VERSION ""

NS_ :

BS_:

BU_: VCU BMS ECUMASTER_GPS_IMU AMK_RL

BO_ 256 VCU_STATUS: 4 Vector__XXX
 SG_ VEHICLE_STATE : 0|2@1+ (1,0) [0|3] "Enum" Vector__XXX
 SG_ TORQUE_PLAUSIBLE : 2|1@1+ (1,0) [0|1] "Bool" Vector__XXX
 SG_ PEDALS_PLAUSIBLE : 3|1@1+ (1,0) [0|1] "Bool" Vector__XXX
 SG_ TORQUE_DERATING : 4|1@1+ (1,0) [0|0] "Bool" Vector__XXX
 SG_ VCU_EEPROM_STATE : 5|2@1+ (1,0) [0|0] "Enum" Vector__XXX
 SG_ CAN_PLAUSIBLE : 7|1@1+ (1,0) [0|1] "Bool" Vector__XXX
 SG_ APPS_1_PLAUSIBLE : 8|1@1+ (1,0) [0|1] "Bool" Vector__XXX
 SG_ APPS_1_CONFIG_PLAUSIBLE : 9|1@1+ (1,0) [0|1] "Bool" Vector__XXX
 SG_ APPS_2_PLAUSIBLE : 10|1@1+ (1,0) [0|1] "Bool" Vector__XXX
 SG_ APPS_2_CONFIG_PLAUSIBLE : 11|1@1+ (1,0) [0|1] "Bool" Vector__XXX
 SG_ BSE_F_PLAUSIBLE : 12|1@1+ (1,0) [0|1] "Bool" Vector__XXX
 SG_ BSE_F_CONFIG_PLAUSIBLE : 13|1@1+ (1,0) [0|1] "Bool" Vector__XXX
 SG_ BSE_R_PLAUSIBLE : 14|1@1+ (1,0) [0|1] "Bool" Vector__XXX
 SG_ BSE_R_CONFIG_PLAUSIBLE : 15|1@1+ (1,0) [0|1] "Bool" Vector__XXX
 SG_ AMK_RL_VALID : 16|1@1+ (1,0) [0|0] "Bool" Vector__XXX
 SG_ AMK_RR_VALID : 17|1@1+ (1,0) [0|0] "Bool" Vector__XXX
 SG_ AMK_FL_VALID : 18|1@1+ (1,0) [0|0] "Bool" Vector__XXX
 SG_ AMK_FR_VALID : 19|1@1+ (1,0) [0|0] "Bool" Vector__XXX
 SG_ GPS_VALID : 20|1@1+ (1,0) [0|0] "Bool" Vector__XXX
 SG_ GLV_BATTERY_VOLTAGE : 24|8@1+ (0.070588235294,0) [0|18] "V" Vector__XXX

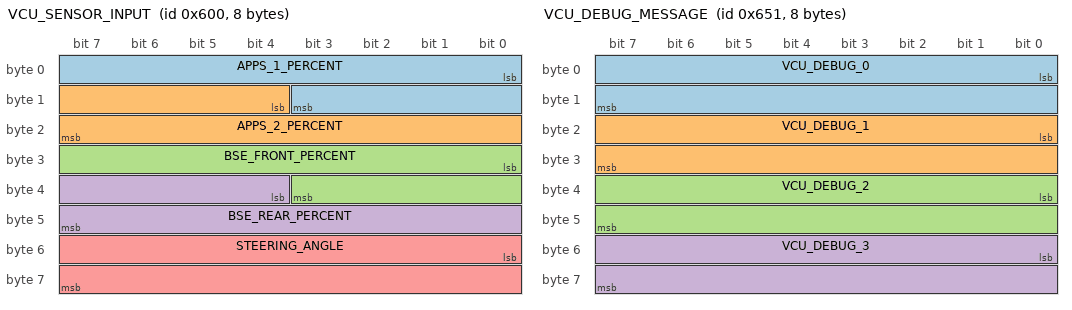
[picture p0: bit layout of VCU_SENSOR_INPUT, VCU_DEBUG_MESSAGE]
BO_ 1536 VCU_SENSOR_INPUT: 8 VCU
 SG_ APPS_1_PERCENT : 0|12@1+ (0.02442002442002442,0) [0|100] "%" Vector__XXX
 SG_ APPS_2_PERCENT : 12|12@1+ (0.02442002442002442,0) [0|100] "%" Vector__XXX
 SG_ BSE_FRONT_PERCENT : 24|12@1+ (0.02442002442002442,0) [0|100] "%" Vector__XXX
 SG_ BSE_REAR_PERCENT : 36|12@1+ (0.02442002442002442,0) [0|100] "%" Vector__XXX
 SG_ STEERING_ANGLE : 48|16@1- (0.005493247882810711,0) [-180|180] "Deg" Vector__XXX

BO_ 1617 VCU_DEBUG_MESSAGE: 8 Vector__XXX
 SG_ VCU_DEBUG_0 : 0|16@1- (0.01,0) [-327.68|327.67] "" Vector__XXX
 SG_ VCU_DEBUG_1 : 16|16@1- (0.01,0) [-327.68|327.67] "" Vector__XXX
 SG_ VCU_DEBUG_2 : 32|16@1- (0.01,0) [-327.68|327.67] "" Vector__XXX
 SG_ VCU_DEBUG_3 : 48|16@1- (0.01,0) [-327.68|327.67] "" Vector__XXX

BO_ 1284 AMK_RL_ERRORS_1: 8 AMK_RL
 SG_ RL_DIAGNOSTIC_NUMBER : 0|32@1+ (1,0) [0|0] "Word" Vector__XXX
 SG_ RL_ERROR_INFO_1 : 32|32@1+ (1,0) [0|0] "Word" Vector__XXX

BO_ 1288 AMK_RL_ERRORS_2: 8 AMK_RL
 SG_ RL_ERROR_INFO_2 : 0|32@1+ (1,0) [0|0] "Word" Vector__XXX
 SG_ RL_ERROR_INFO_3 : 32|32@1+ (1,0) [0|0] "Word" Vector__XXX

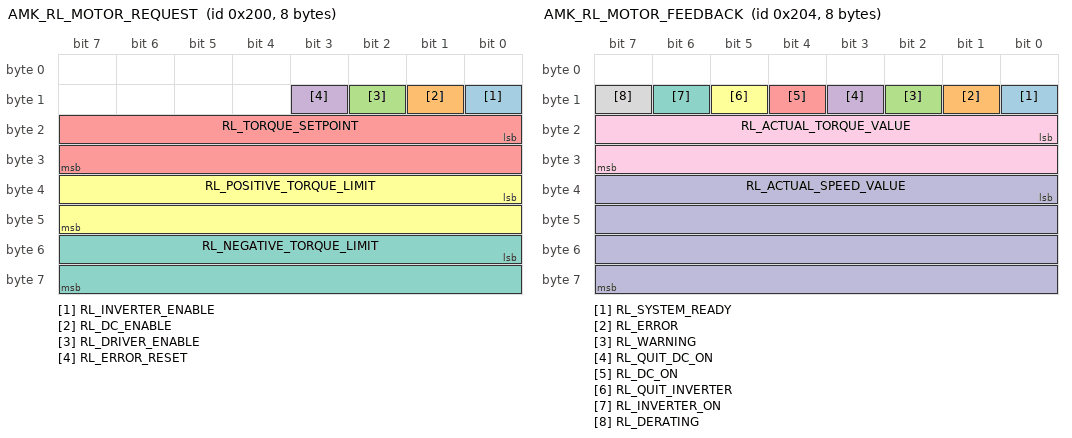
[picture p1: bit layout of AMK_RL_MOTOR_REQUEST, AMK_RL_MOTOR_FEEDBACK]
BO_ 512 AMK_RL_MOTOR_REQUEST: 8 AMK_RL
 SG_ RL_INVERTER_ENABLE : 8|1@1+ (1,0) [0|0] "" Vector__XXX
 SG_ RL_DC_ENABLE : 9|1@1+ (1,0) [0|0] "" Vector__XXX
 SG_ RL_DRIVER_ENABLE : 10|1@1+ (1,0) [0|0] "" Vector__XXX
 SG_ RL_ERROR_RESET : 11|1@1+ (1,0) [0|0] "" Vector__XXX
 SG_ RL_TORQUE_SETPOINT : 16|16@1- (0.0098,0) [-21|21] "Nm" Vector__XXX
 SG_ RL_POSITIVE_TORQUE_LIMIT : 32|16@1- (0.0098,0) [0|21] "Nm" Vector__XXX
 SG_ RL_NEGATIVE_TORQUE_LIMIT : 48|16@1- (0.0098,0) [0|21] "Nm" Vector__XXX

BO_ 516 AMK_RL_MOTOR_FEEDBACK: 8 AMK_RL
 SG_ RL_SYSTEM_READY : 8|1@1+ (1,0) [0|0] "Bool" Vector__XXX
 SG_ RL_ERROR : 9|1@1+ (1,0) [0|0] "Bool" Vector__XXX
 SG_ RL_WARNING : 10|1@1+ (1,0) [0|0] "Bool" Vector__XXX
 SG_ RL_QUIT_DC_ON : 11|1@1+ (1,0) [0|0] "Bool" Vector__XXX
 SG_ RL_DC_ON : 12|1@1+ (1,0) [0|0] "Bool" Vector__XXX
 SG_ RL_QUIT_INVERTER : 13|1@1+ (1,0) [0|0] "Bool" Vector__XXX
 SG_ RL_INVERTER_ON : 14|1@1+ (1,0) [0|0] "Bool" Vector__XXX
 SG_ RL_DERATING : 15|1@1+ (1,0) [0|0] "Bool" Vector__XXX
 SG_ RL_ACTUAL_TORQUE_VALUE : 16|16@1- (0.0098,0) [0|0] "Nm" Vector__XXX
 SG_ RL_ACTUAL_SPEED_VALUE : 32|32@1- (0.00001,0) [0|0] "RPM" Vector__XXX

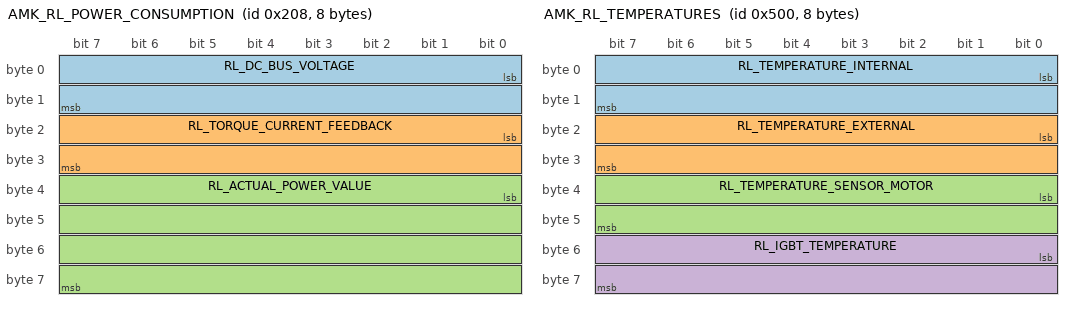
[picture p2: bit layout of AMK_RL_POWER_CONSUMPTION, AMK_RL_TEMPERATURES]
BO_ 520 AMK_RL_POWER_CONSUMPTION: 8 AMK_RL
 SG_ RL_DC_BUS_VOLTAGE : 0|16@1+ (1,0) [0|0] "V" Vector__XXX
 SG_ RL_TORQUE_CURRENT_FEEDBACK : 16|16@1- (1,0) [0|0] "A" Vector__XXX
 SG_ RL_ACTUAL_POWER_VALUE : 32|32@1+ (1,0) [0|0] "W" Vector__XXX

BO_ 1280 AMK_RL_TEMPERATURES: 8 AMK_RL
 SG_ RL_TEMPERATURE_INTERNAL : 0|16@1- (0.1,0) [0|0] "C" Vector__XXX
 SG_ RL_TEMPERATURE_EXTERNAL : 16|16@1- (0.1,0) [0|0] "C" Vector__XXX
 SG_ RL_TEMPERATURE_SENSOR_MOTOR : 32|16@1+ (0.1,0) [0|0] "C" Vector__XXX
 SG_ RL_IGBT_TEMPERATURE : 48|16@1- (0.1,0) [0|0] "C" Vector__XXX

BO_ 1024 ECUMASTER_GPS_POSITION: 8 ECUMASTER_GPS_IMU
 SG_ LATITUDE : 7|32@0- (1e-7,0) [-90|90] "deg" Vector__XXX
 SG_ LONGITUDE : 39|32@0- (1e-7,0) [-180|180] "deg" Vector__XXX

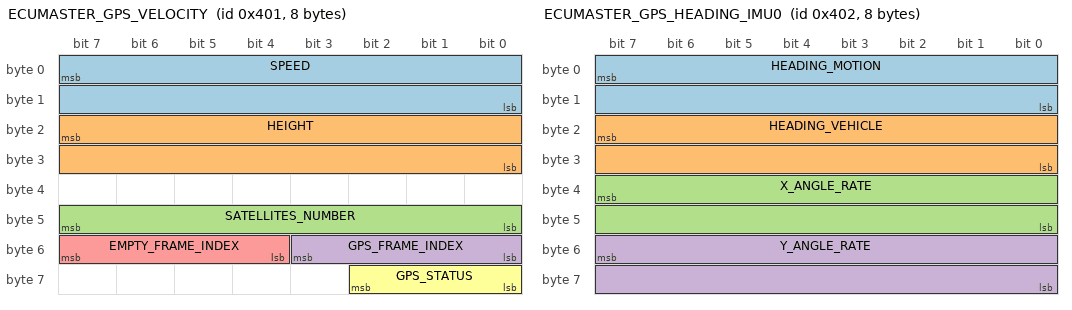
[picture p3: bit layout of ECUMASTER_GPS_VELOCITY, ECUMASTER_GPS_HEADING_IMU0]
BO_ 1025 ECUMASTER_GPS_VELOCITY: 8 ECUMASTER_GPS_IMU
 SG_ SPEED : 7|16@0- (0.036,0) [-1179|1179] "km/h" Vector__XXX
 SG_ HEIGHT : 23|16@0- (1,0) [-32768|32767] "m" Vector__XXX
 SG_ SATELLITES_NUMBER : 47|8@0+ (1,0) [0|72] "" Vector__XXX
 SG_ GPS_FRAME_INDEX : 51|4@0+ (1,0) [0|16] "" Vector__XXX
 SG_ EMPTY_FRAME_INDEX : 55|4@0+ (1,0) [0|16] "" Vector__XXX
 SG_ GPS_STATUS : 58|3@0+ (1,0) [1|5] "" Vector__XXX

BO_ 1026 ECUMASTER_GPS_HEADING_IMU0: 8 ECUMASTER_GPS_IMU
 SG_ HEADING_MOTION : 7|16@0+ (1,0) [0|360] "deg" Vector__XXX
 SG_ HEADING_VEHICLE : 23|16@0+ (1,0) [0|360] "deg" Vector__XXX
 SG_ X_ANGLE_RATE : 39|16@0- (0.01,0) [-250|250] "deg/s" Vector__XXX
 SG_ Y_ANGLE_RATE : 55|16@0- (0.01,0) [-250|250] "deg/s" Vector__XXX

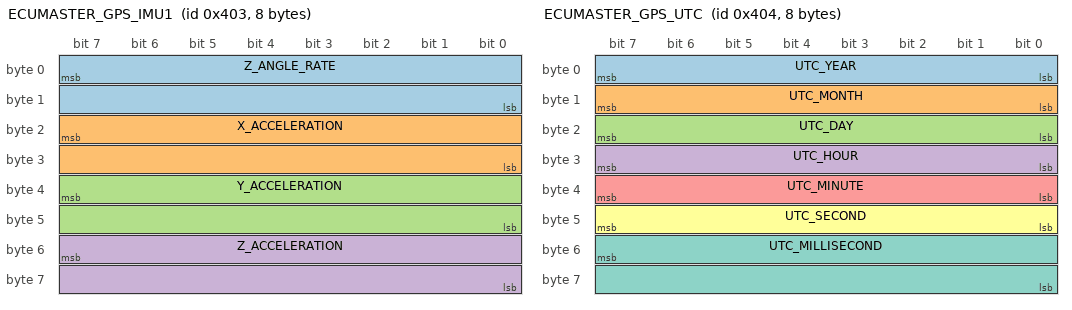
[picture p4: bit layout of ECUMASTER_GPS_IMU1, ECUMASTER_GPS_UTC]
BO_ 1027 ECUMASTER_GPS_IMU1: 8 ECUMASTER_GPS_IMU
 SG_ Z_ANGLE_RATE : 7|16@0- (0.01,0) [-250|250] "deg/s" Vector__XXX
 SG_ X_ACCELERATION : 23|16@0- (0.01,0) [-4|4] "g" Vector__XXX
 SG_ Y_ACCELERATION : 39|16@0- (0.01,0) [-4|4] "g" Vector__XXX
 SG_ Z_ACCELERATION : 55|16@0- (0.01,0) [-4|4] "g" Vector__XXX

BO_ 1028 ECUMASTER_GPS_UTC: 8 ECUMASTER_GPS_IMU
 SG_ UTC_YEAR : 7|8@0+ (1,2000) [2000|2255] "years" Vector__XXX
 SG_ UTC_MONTH : 15|8@0+ (1,0) [1|12] "months" Vector__XXX
 SG_ UTC_DAY : 23|8@0+ (1,0) [1|31] "days" Vector__XXX
 SG_ UTC_HOUR : 31|8@0+ (1,0) [0|23] "hours" Vector__XXX
 SG_ UTC_MINUTE : 39|8@0+ (1,0) [0|59] "minutes" Vector__XXX
 SG_ UTC_SECOND : 47|8@0+ (1,0) [0|59] "s" Vector__XXX
 SG_ UTC_MILLISECOND : 55|16@0+ (0.0152587890625,0) [0|999.99] "ms" Vector__XXX

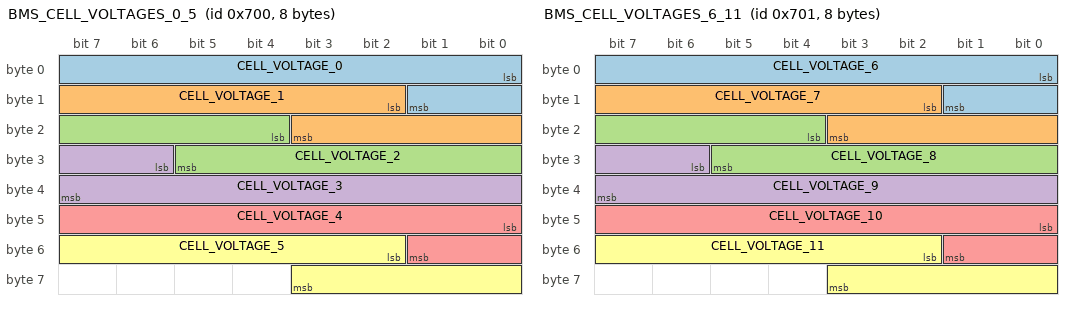
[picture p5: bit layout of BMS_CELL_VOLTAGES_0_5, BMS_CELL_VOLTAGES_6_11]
BO_ 1792 BMS_CELL_VOLTAGES_0_5: 8 BMS
 SG_ CELL_VOLTAGE_0 : 0|10@1+ (0.0078125,0) [0|8] "V" Vector__XXX
 SG_ CELL_VOLTAGE_1 : 10|10@1+ (0.0078125,0) [0|8] "V" Vector__XXX
 SG_ CELL_VOLTAGE_2 : 20|10@1+ (0.0078125,0) [0|8] "V" Vector__XXX
 SG_ CELL_VOLTAGE_3 : 30|10@1+ (0.0078125,0) [0|8] "V" Vector__XXX
 SG_ CELL_VOLTAGE_4 : 40|10@1+ (0.0078125,0) [0|8] "V" Vector__XXX
 SG_ CELL_VOLTAGE_5 : 50|10@1+ (0.0078125,0) [0|8] "V" Vector__XXX

BO_ 1793 BMS_CELL_VOLTAGES_6_11: 8 BMS
 SG_ CELL_VOLTAGE_6 : 0|10@1+ (0.0078125,0) [0|8] "V" Vector__XXX
 SG_ CELL_VOLTAGE_7 : 10|10@1+ (0.0078125,0) [0|8] "V" Vector__XXX
 SG_ CELL_VOLTAGE_8 : 20|10@1+ (0.0078125,0) [0|8] "V" Vector__XXX
 SG_ CELL_VOLTAGE_9 : 30|10@1+ (0.0078125,0) [0|8] "V" Vector__XXX
 SG_ CELL_VOLTAGE_10 : 40|10@1+ (0.0078125,0) [0|8] "V" Vector__XXX
 SG_ CELL_VOLTAGE_11 : 50|10@1+ (0.0078125,0) [0|8] "V" Vector__XXX

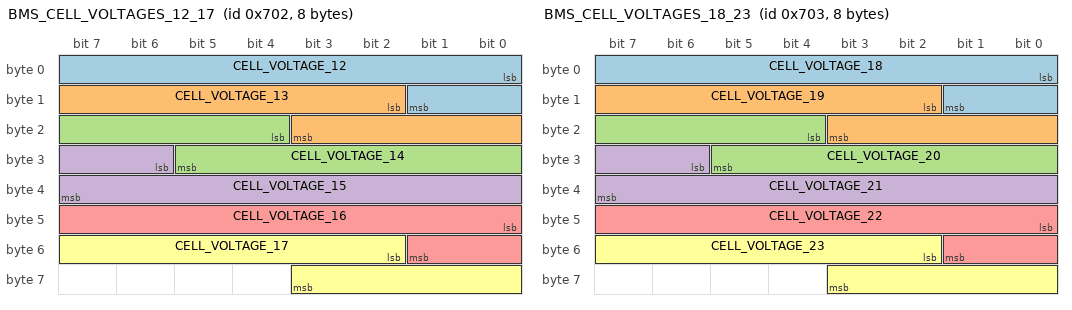
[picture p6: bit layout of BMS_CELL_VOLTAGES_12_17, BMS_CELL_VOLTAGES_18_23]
BO_ 1794 BMS_CELL_VOLTAGES_12_17: 8 BMS
 SG_ CELL_VOLTAGE_12 : 0|10@1+ (0.0078125,0) [0|8] "V" Vector__XXX
 SG_ CELL_VOLTAGE_13 : 10|10@1+ (0.0078125,0) [0|8] "V" Vector__XXX
 SG_ CELL_VOLTAGE_14 : 20|10@1+ (0.0078125,0) [0|8] "V" Vector__XXX
 SG_ CELL_VOLTAGE_15 : 30|10@1+ (0.0078125,0) [0|8] "V" Vector__XXX
 SG_ CELL_VOLTAGE_16 : 40|10@1+ (0.0078125,0) [0|8] "V" Vector__XXX
 SG_ CELL_VOLTAGE_17 : 50|10@1+ (0.0078125,0) [0|8] "V" Vector__XXX

BO_ 1795 BMS_CELL_VOLTAGES_18_23: 8 BMS
 SG_ CELL_VOLTAGE_18 : 0|10@1+ (0.0078125,0) [0|8] "V" Vector__XXX
 SG_ CELL_VOLTAGE_19 : 10|10@1+ (0.0078125,0) [0|8] "V" Vector__XXX
 SG_ CELL_VOLTAGE_20 : 20|10@1+ (0.0078125,0) [0|8] "V" Vector__XXX
 SG_ CELL_VOLTAGE_21 : 30|10@1+ (0.0078125,0) [0|8] "V" Vector__XXX
 SG_ CELL_VOLTAGE_22 : 40|10@1+ (0.0078125,0) [0|8] "V" Vector__XXX
 SG_ CELL_VOLTAGE_23 : 50|10@1+ (0.0078125,0) [0|8] "V" Vector__XXX

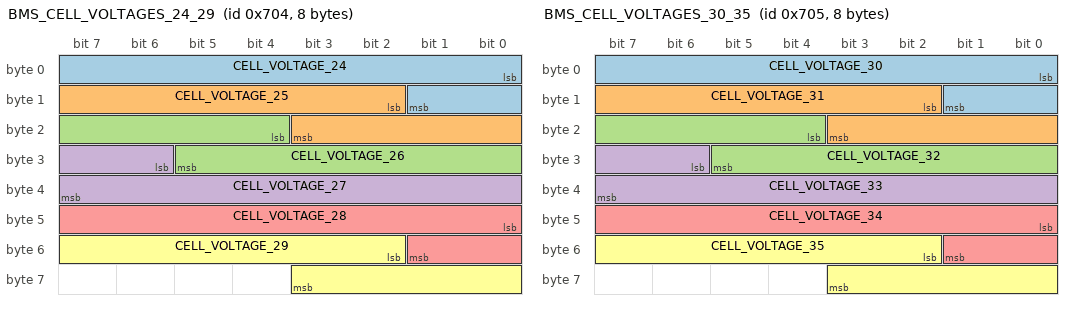
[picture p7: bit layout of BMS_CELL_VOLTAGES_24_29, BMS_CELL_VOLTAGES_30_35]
BO_ 1796 BMS_CELL_VOLTAGES_24_29: 8 BMS
 SG_ CELL_VOLTAGE_24 : 0|10@1+ (0.0078125,0) [0|8] "V" Vector__XXX
 SG_ CELL_VOLTAGE_25 : 10|10@1+ (0.0078125,0) [0|8] "V" Vector__XXX
 SG_ CELL_VOLTAGE_26 : 20|10@1+ (0.0078125,0) [0|8] "V" Vector__XXX
 SG_ CELL_VOLTAGE_27 : 30|10@1+ (0.0078125,0) [0|8] "V" Vector__XXX
 SG_ CELL_VOLTAGE_28 : 40|10@1+ (0.0078125,0) [0|8] "V" Vector__XXX
 SG_ CELL_VOLTAGE_29 : 50|10@1+ (0.0078125,0) [0|8] "V" Vector__XXX

BO_ 1797 BMS_CELL_VOLTAGES_30_35: 8 BMS
 SG_ CELL_VOLTAGE_30 : 0|10@1+ (0.0078125,0) [0|8] "V" Vector__XXX
 SG_ CELL_VOLTAGE_31 : 10|10@1+ (0.0078125,0) [0|8] "V" Vector__XXX
 SG_ CELL_VOLTAGE_32 : 20|10@1+ (0.0078125,0) [0|8] "V" Vector__XXX
 SG_ CELL_VOLTAGE_33 : 30|10@1+ (0.0078125,0) [0|8] "V" Vector__XXX
 SG_ CELL_VOLTAGE_34 : 40|10@1+ (0.0078125,0) [0|8] "V" Vector__XXX
 SG_ CELL_VOLTAGE_35 : 50|10@1+ (0.0078125,0) [0|8] "V" Vector__XXX

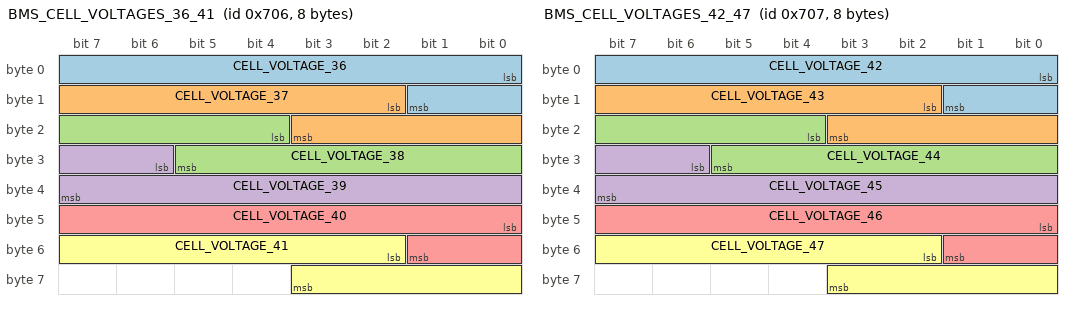
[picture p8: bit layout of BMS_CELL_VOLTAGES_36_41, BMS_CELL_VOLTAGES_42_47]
BO_ 1798 BMS_CELL_VOLTAGES_36_41: 8 BMS
 SG_ CELL_VOLTAGE_36 : 0|10@1+ (0.0078125,0) [0|8] "V" Vector__XXX
 SG_ CELL_VOLTAGE_37 : 10|10@1+ (0.0078125,0) [0|8] "V" Vector__XXX
 SG_ CELL_VOLTAGE_38 : 20|10@1+ (0.0078125,0) [0|8] "V" Vector__XXX
 SG_ CELL_VOLTAGE_39 : 30|10@1+ (0.0078125,0) [0|8] "V" Vector__XXX
 SG_ CELL_VOLTAGE_40 : 40|10@1+ (0.0078125,0) [0|8] "V" Vector__XXX
 SG_ CELL_VOLTAGE_41 : 50|10@1+ (0.0078125,0) [0|8] "V" Vector__XXX

BO_ 1799 BMS_CELL_VOLTAGES_42_47: 8 BMS
 SG_ CELL_VOLTAGE_42 : 0|10@1+ (0.0078125,0) [0|8] "V" Vector__XXX
 SG_ CELL_VOLTAGE_43 : 10|10@1+ (0.0078125,0) [0|8] "V" Vector__XXX
 SG_ CELL_VOLTAGE_44 : 20|10@1+ (0.0078125,0) [0|8] "V" Vector__XXX
 SG_ CELL_VOLTAGE_45 : 30|10@1+ (0.0078125,0) [0|8] "V" Vector__XXX
 SG_ CELL_VOLTAGE_46 : 40|10@1+ (0.0078125,0) [0|8] "V" Vector__XXX
 SG_ CELL_VOLTAGE_47 : 50|10@1+ (0.0078125,0) [0|8] "V" Vector__XXX

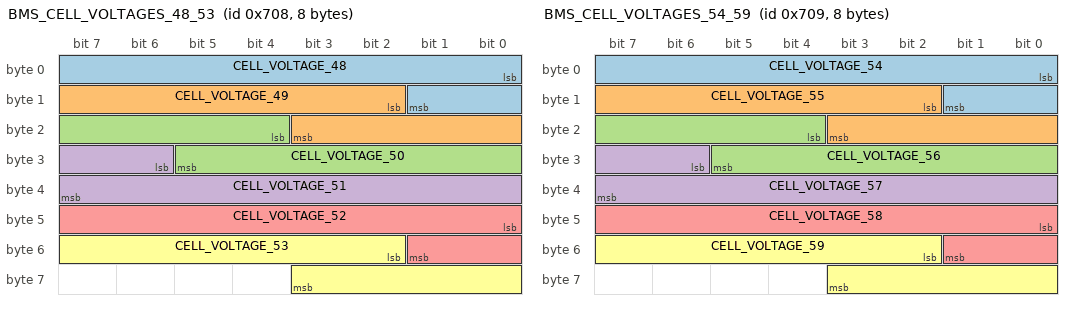
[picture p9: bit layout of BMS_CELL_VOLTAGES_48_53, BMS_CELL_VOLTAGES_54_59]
BO_ 1800 BMS_CELL_VOLTAGES_48_53: 8 BMS
 SG_ CELL_VOLTAGE_48 : 0|10@1+ (0.0078125,0) [0|8] "V" Vector__XXX
 SG_ CELL_VOLTAGE_49 : 10|10@1+ (0.0078125,0) [0|8] "V" Vector__XXX
 SG_ CELL_VOLTAGE_50 : 20|10@1+ (0.0078125,0) [0|8] "V" Vector__XXX
 SG_ CELL_VOLTAGE_51 : 30|10@1+ (0.0078125,0) [0|8] "V" Vector__XXX
 SG_ CELL_VOLTAGE_52 : 40|10@1+ (0.0078125,0) [0|8] "V" Vector__XXX
 SG_ CELL_VOLTAGE_53 : 50|10@1+ (0.0078125,0) [0|8] "V" Vector__XXX

BO_ 1801 BMS_CELL_VOLTAGES_54_59: 8 BMS
 SG_ CELL_VOLTAGE_54 : 0|10@1+ (0.0078125,0) [0|8] "V" Vector__XXX
 SG_ CELL_VOLTAGE_55 : 10|10@1+ (0.0078125,0) [0|8] "V" Vector__XXX
 SG_ CELL_VOLTAGE_56 : 20|10@1+ (0.0078125,0) [0|8] "V" Vector__XXX
 SG_ CELL_VOLTAGE_57 : 30|10@1+ (0.0078125,0) [0|8] "V" Vector__XXX
 SG_ CELL_VOLTAGE_58 : 40|10@1+ (0.0078125,0) [0|8] "V" Vector__XXX
 SG_ CELL_VOLTAGE_59 : 50|10@1+ (0.0078125,0) [0|8] "V" Vector__XXX

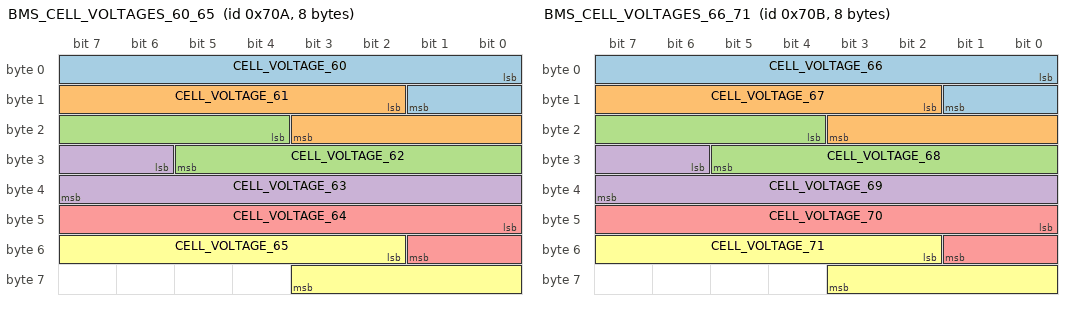
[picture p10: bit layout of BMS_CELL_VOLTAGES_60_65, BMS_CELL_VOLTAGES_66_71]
BO_ 1802 BMS_CELL_VOLTAGES_60_65: 8 BMS
 SG_ CELL_VOLTAGE_60 : 0|10@1+ (0.0078125,0) [0|8] "V" Vector__XXX
 SG_ CELL_VOLTAGE_61 : 10|10@1+ (0.0078125,0) [0|8] "V" Vector__XXX
 SG_ CELL_VOLTAGE_62 : 20|10@1+ (0.0078125,0) [0|8] "V" Vector__XXX
 SG_ CELL_VOLTAGE_63 : 30|10@1+ (0.0078125,0) [0|8] "V" Vector__XXX
 SG_ CELL_VOLTAGE_64 : 40|10@1+ (0.0078125,0) [0|8] "V" Vector__XXX
 SG_ CELL_VOLTAGE_65 : 50|10@1+ (0.0078125,0) [0|8] "V" Vector__XXX

BO_ 1803 BMS_CELL_VOLTAGES_66_71: 8 BMS
 SG_ CELL_VOLTAGE_66 : 0|10@1+ (0.0078125,0) [0|8] "V" Vector__XXX
 SG_ CELL_VOLTAGE_67 : 10|10@1+ (0.0078125,0) [0|8] "V" Vector__XXX
 SG_ CELL_VOLTAGE_68 : 20|10@1+ (0.0078125,0) [0|8] "V" Vector__XXX
 SG_ CELL_VOLTAGE_69 : 30|10@1+ (0.0078125,0) [0|8] "V" Vector__XXX
 SG_ CELL_VOLTAGE_70 : 40|10@1+ (0.0078125,0) [0|8] "V" Vector__XXX
 SG_ CELL_VOLTAGE_71 : 50|10@1+ (0.0078125,0) [0|8] "V" Vector__XXX

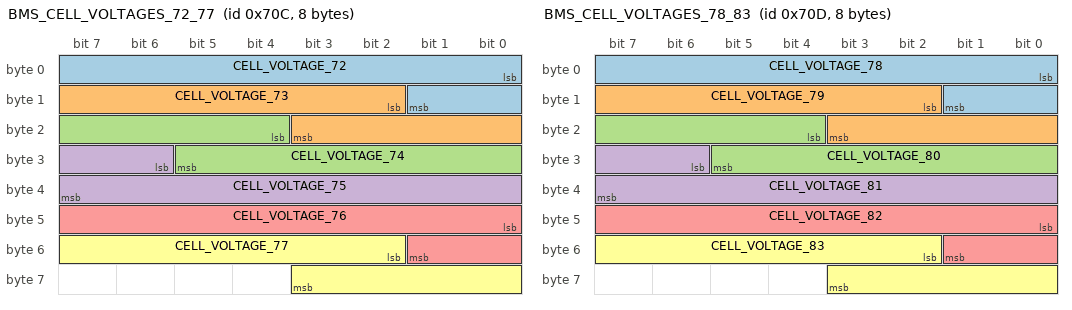
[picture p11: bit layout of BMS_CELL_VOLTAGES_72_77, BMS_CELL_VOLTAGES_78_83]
BO_ 1804 BMS_CELL_VOLTAGES_72_77: 8 BMS
 SG_ CELL_VOLTAGE_72 : 0|10@1+ (0.0078125,0) [0|8] "V" Vector__XXX
 SG_ CELL_VOLTAGE_73 : 10|10@1+ (0.0078125,0) [0|8] "V" Vector__XXX
 SG_ CELL_VOLTAGE_74 : 20|10@1+ (0.0078125,0) [0|8] "V" Vector__XXX
 SG_ CELL_VOLTAGE_75 : 30|10@1+ (0.0078125,0) [0|8] "V" Vector__XXX
 SG_ CELL_VOLTAGE_76 : 40|10@1+ (0.0078125,0) [0|8] "V" Vector__XXX
 SG_ CELL_VOLTAGE_77 : 50|10@1+ (0.0078125,0) [0|8] "V" Vector__XXX

BO_ 1805 BMS_CELL_VOLTAGES_78_83: 8 BMS
 SG_ CELL_VOLTAGE_78 : 0|10@1+ (0.0078125,0) [0|8] "V" Vector__XXX
 SG_ CELL_VOLTAGE_79 : 10|10@1+ (0.0078125,0) [0|8] "V" Vector__XXX
 SG_ CELL_VOLTAGE_80 : 20|10@1+ (0.0078125,0) [0|8] "V" Vector__XXX
 SG_ CELL_VOLTAGE_81 : 30|10@1+ (0.0078125,0) [0|8] "V" Vector__XXX
 SG_ CELL_VOLTAGE_82 : 40|10@1+ (0.0078125,0) [0|8] "V" Vector__XXX
 SG_ CELL_VOLTAGE_83 : 50|10@1+ (0.0078125,0) [0|8] "V" Vector__XXX

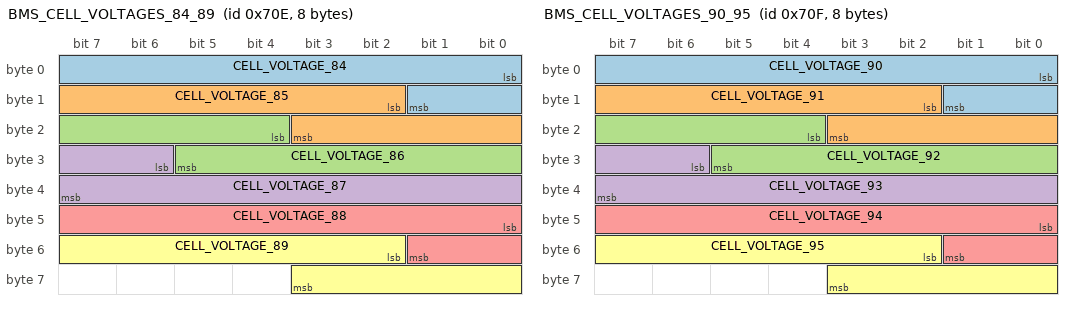
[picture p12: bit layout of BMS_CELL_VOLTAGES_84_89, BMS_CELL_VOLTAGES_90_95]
BO_ 1806 BMS_CELL_VOLTAGES_84_89: 8 BMS
 SG_ CELL_VOLTAGE_84 : 0|10@1+ (0.0078125,0) [0|8] "V" Vector__XXX
 SG_ CELL_VOLTAGE_85 : 10|10@1+ (0.0078125,0) [0|8] "V" Vector__XXX
 SG_ CELL_VOLTAGE_86 : 20|10@1+ (0.0078125,0) [0|8] "V" Vector__XXX
 SG_ CELL_VOLTAGE_87 : 30|10@1+ (0.0078125,0) [0|8] "V" Vector__XXX
 SG_ CELL_VOLTAGE_88 : 40|10@1+ (0.0078125,0) [0|8] "V" Vector__XXX
 SG_ CELL_VOLTAGE_89 : 50|10@1+ (0.0078125,0) [0|8] "V" Vector__XXX

BO_ 1807 BMS_CELL_VOLTAGES_90_95: 8 BMS
 SG_ CELL_VOLTAGE_90 : 0|10@1+ (0.0078125,0) [0|8] "V" Vector__XXX
 SG_ CELL_VOLTAGE_91 : 10|10@1+ (0.0078125,0) [0|8] "V" Vector__XXX
 SG_ CELL_VOLTAGE_92 : 20|10@1+ (0.0078125,0) [0|8] "V" Vector__XXX
 SG_ CELL_VOLTAGE_93 : 30|10@1+ (0.0078125,0) [0|8] "V" Vector__XXX
 SG_ CELL_VOLTAGE_94 : 40|10@1+ (0.0078125,0) [0|8] "V" Vector__XXX
 SG_ CELL_VOLTAGE_95 : 50|10@1+ (0.0078125,0) [0|8] "V" Vector__XXX

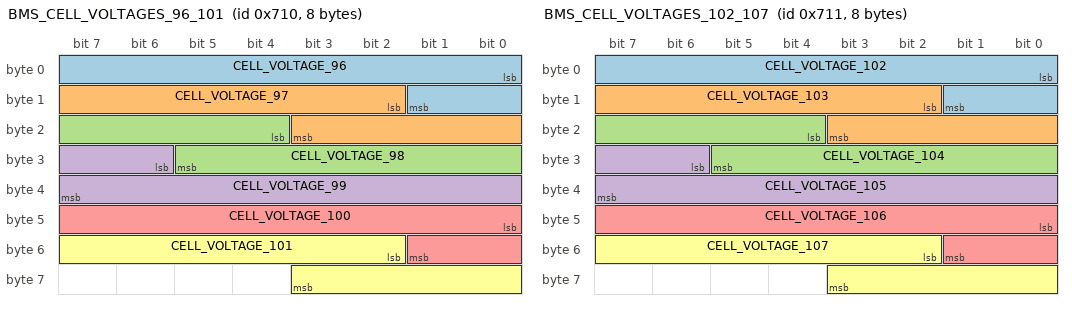
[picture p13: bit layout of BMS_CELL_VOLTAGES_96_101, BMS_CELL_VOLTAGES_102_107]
BO_ 1808 BMS_CELL_VOLTAGES_96_101: 8 BMS
 SG_ CELL_VOLTAGE_96 : 0|10@1+ (0.0078125,0) [0|8] "V" Vector__XXX
 SG_ CELL_VOLTAGE_97 : 10|10@1+ (0.0078125,0) [0|8] "V" Vector__XXX
 SG_ CELL_VOLTAGE_98 : 20|10@1+ (0.0078125,0) [0|8] "V" Vector__XXX
 SG_ CELL_VOLTAGE_99 : 30|10@1+ (0.0078125,0) [0|8] "V" Vector__XXX
 SG_ CELL_VOLTAGE_100 : 40|10@1+ (0.0078125,0) [0|8] "V" Vector__XXX
 SG_ CELL_VOLTAGE_101 : 50|10@1+ (0.0078125,0) [0|8] "V" Vector__XXX

BO_ 1809 BMS_CELL_VOLTAGES_102_107: 8 BMS
 SG_ CELL_VOLTAGE_102 : 0|10@1+ (0.0078125,0) [0|8] "V" Vector__XXX
 SG_ CELL_VOLTAGE_103 : 10|10@1+ (0.0078125,0) [0|8] "V" Vector__XXX
 SG_ CELL_VOLTAGE_104 : 20|10@1+ (0.0078125,0) [0|8] "V" Vector__XXX
 SG_ CELL_VOLTAGE_105 : 30|10@1+ (0.0078125,0) [0|8] "V" Vector__XXX
 SG_ CELL_VOLTAGE_106 : 40|10@1+ (0.0078125,0) [0|8] "V" Vector__XXX
 SG_ CELL_VOLTAGE_107 : 50|10@1+ (0.0078125,0) [0|8] "V" Vector__XXX

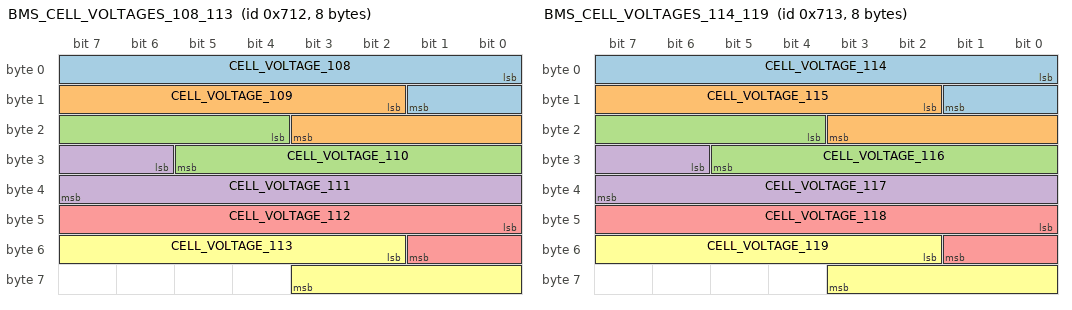
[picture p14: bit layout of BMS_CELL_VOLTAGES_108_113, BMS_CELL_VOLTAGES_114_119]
BO_ 1810 BMS_CELL_VOLTAGES_108_113: 8 BMS
 SG_ CELL_VOLTAGE_108 : 0|10@1+ (0.0078125,0) [0|8] "V" Vector__XXX
 SG_ CELL_VOLTAGE_109 : 10|10@1+ (0.0078125,0) [0|8] "V" Vector__XXX
 SG_ CELL_VOLTAGE_110 : 20|10@1+ (0.0078125,0) [0|8] "V" Vector__XXX
 SG_ CELL_VOLTAGE_111 : 30|10@1+ (0.0078125,0) [0|8] "V" Vector__XXX
 SG_ CELL_VOLTAGE_112 : 40|10@1+ (0.0078125,0) [0|8] "V" Vector__XXX
 SG_ CELL_VOLTAGE_113 : 50|10@1+ (0.0078125,0) [0|8] "V" Vector__XXX

BO_ 1811 BMS_CELL_VOLTAGES_114_119: 8 BMS
 SG_ CELL_VOLTAGE_114 : 0|10@1+ (0.0078125,0) [0|8] "V" Vector__XXX
 SG_ CELL_VOLTAGE_115 : 10|10@1+ (0.0078125,0) [0|8] "V" Vector__XXX
 SG_ CELL_VOLTAGE_116 : 20|10@1+ (0.0078125,0) [0|8] "V" Vector__XXX
 SG_ CELL_VOLTAGE_117 : 30|10@1+ (0.0078125,0) [0|8] "V" Vector__XXX
 SG_ CELL_VOLTAGE_118 : 40|10@1+ (0.0078125,0) [0|8] "V" Vector__XXX
 SG_ CELL_VOLTAGE_119 : 50|10@1+ (0.0078125,0) [0|8] "V" Vector__XXX

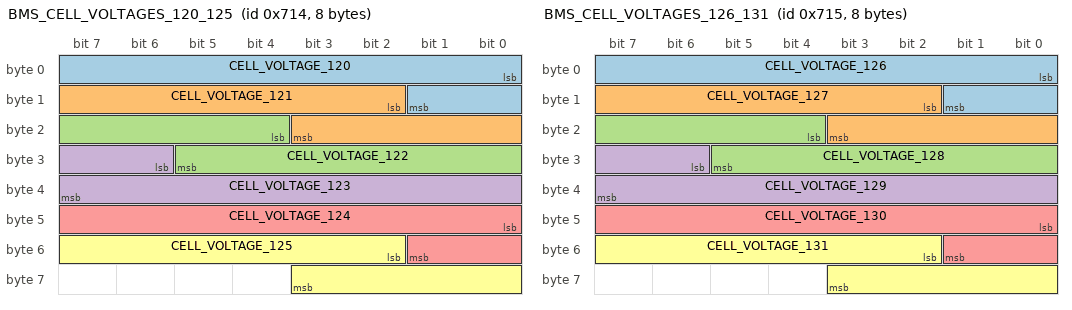
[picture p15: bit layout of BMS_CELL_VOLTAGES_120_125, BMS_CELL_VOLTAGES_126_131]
BO_ 1812 BMS_CELL_VOLTAGES_120_125: 8 BMS
 SG_ CELL_VOLTAGE_120 : 0|10@1+ (0.0078125,0) [0|8] "V" Vector__XXX
 SG_ CELL_VOLTAGE_121 : 10|10@1+ (0.0078125,0) [0|8] "V" Vector__XXX
 SG_ CELL_VOLTAGE_122 : 20|10@1+ (0.0078125,0) [0|8] "V" Vector__XXX
 SG_ CELL_VOLTAGE_123 : 30|10@1+ (0.0078125,0) [0|8] "V" Vector__XXX
 SG_ CELL_VOLTAGE_124 : 40|10@1+ (0.0078125,0) [0|8] "V" Vector__XXX
 SG_ CELL_VOLTAGE_125 : 50|10@1+ (0.0078125,0) [0|8] "V" Vector__XXX

BO_ 1813 BMS_CELL_VOLTAGES_126_131: 8 BMS
 SG_ CELL_VOLTAGE_126 : 0|10@1+ (0.0078125,0) [0|8] "V" Vector__XXX
 SG_ CELL_VOLTAGE_127 : 10|10@1+ (0.0078125,0) [0|8] "V" Vector__XXX
 SG_ CELL_VOLTAGE_128 : 20|10@1+ (0.0078125,0) [0|8] "V" Vector__XXX
 SG_ CELL_VOLTAGE_129 : 30|10@1+ (0.0078125,0) [0|8] "V" Vector__XXX
 SG_ CELL_VOLTAGE_130 : 40|10@1+ (0.0078125,0) [0|8] "V" Vector__XXX
 SG_ CELL_VOLTAGE_131 : 50|10@1+ (0.0078125,0) [0|8] "V" Vector__XXX

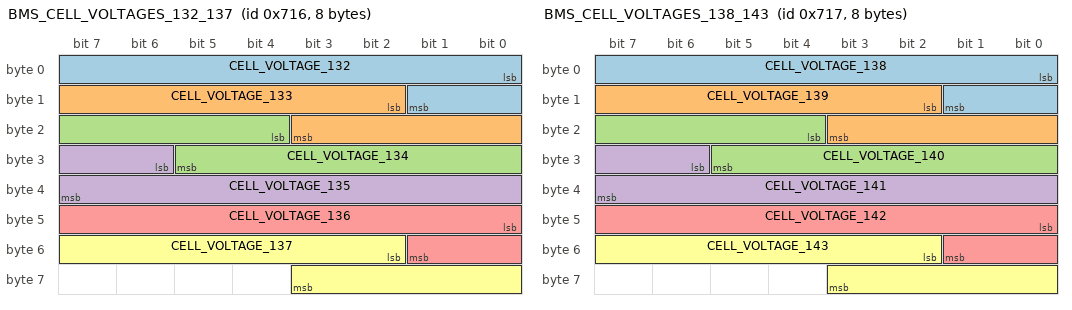
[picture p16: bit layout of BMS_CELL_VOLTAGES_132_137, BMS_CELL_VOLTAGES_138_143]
BO_ 1814 BMS_CELL_VOLTAGES_132_137: 8 BMS
 SG_ CELL_VOLTAGE_132 : 0|10@1+ (0.0078125,0) [0|8] "V" Vector__XXX
 SG_ CELL_VOLTAGE_133 : 10|10@1+ (0.0078125,0) [0|8] "V" Vector__XXX
 SG_ CELL_VOLTAGE_134 : 20|10@1+ (0.0078125,0) [0|8] "V" Vector__XXX
 SG_ CELL_VOLTAGE_135 : 30|10@1+ (0.0078125,0) [0|8] "V" Vector__XXX
 SG_ CELL_VOLTAGE_136 : 40|10@1+ (0.0078125,0) [0|8] "V" Vector__XXX
 SG_ CELL_VOLTAGE_137 : 50|10@1+ (0.0078125,0) [0|8] "V" Vector__XXX

BO_ 1815 BMS_CELL_VOLTAGES_138_143: 8 BMS
 SG_ CELL_VOLTAGE_138 : 0|10@1+ (0.0078125,0) [0|8] "V" Vector__XXX
 SG_ CELL_VOLTAGE_139 : 10|10@1+ (0.0078125,0) [0|8] "V" Vector__XXX
 SG_ CELL_VOLTAGE_140 : 20|10@1+ (0.0078125,0) [0|8] "V" Vector__XXX
 SG_ CELL_VOLTAGE_141 : 30|10@1+ (0.0078125,0) [0|8] "V" Vector__XXX
 SG_ CELL_VOLTAGE_142 : 40|10@1+ (0.0078125,0) [0|8] "V" Vector__XXX
 SG_ CELL_VOLTAGE_143 : 50|10@1+ (0.0078125,0) [0|8] "V" Vector__XXX

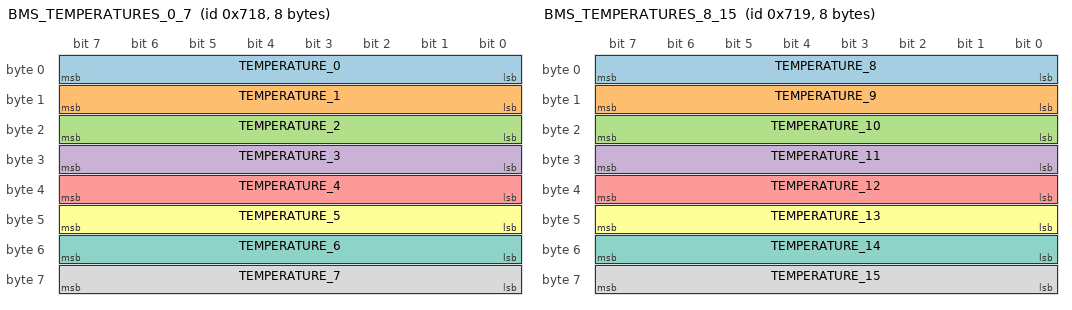
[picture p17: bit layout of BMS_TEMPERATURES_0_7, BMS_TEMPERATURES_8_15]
BO_ 1816 BMS_TEMPERATURES_0_7: 8 BMS
 SG_ TEMPERATURE_0 : 0|8@1+ (0.5,-28) [-28|99.5] "C" Vector__XXX
 SG_ TEMPERATURE_1 : 8|8@1+ (0.5,-28) [-28|99.5] "C" Vector__XXX
 SG_ TEMPERATURE_2 : 16|8@1+ (0.5,-28) [-28|99.5] "C" Vector__XXX
 SG_ TEMPERATURE_3 : 24|8@1+ (0.5,-28) [-28|99.5] "C" Vector__XXX
 SG_ TEMPERATURE_4 : 32|8@1+ (0.5,-28) [-28|99.5] "C" Vector__XXX
 SG_ TEMPERATURE_5 : 40|8@1+ (0.5,-28) [-28|99.5] "C" Vector__XXX
 SG_ TEMPERATURE_6 : 48|8@1+ (0.5,-28) [-28|99.5] "C" Vector__XXX
 SG_ TEMPERATURE_7 : 56|8@1+ (0.5,-28) [-28|99.5] "C" Vector__XXX

BO_ 1817 BMS_TEMPERATURES_8_15: 8 BMS
 SG_ TEMPERATURE_8 : 0|8@1+ (0.5,-28) [-28|99.5] "C" Vector__XXX
 SG_ TEMPERATURE_9 : 8|8@1+ (0.5,-28) [-28|99.5] "C" Vector__XXX
 SG_ TEMPERATURE_10 : 16|8@1+ (0.5,-28) [-28|99.5] "C" Vector__XXX
 SG_ TEMPERATURE_11 : 24|8@1+ (0.5,-28) [-28|99.5] "C" Vector__XXX
 SG_ TEMPERATURE_12 : 32|8@1+ (0.5,-28) [-28|99.5] "C" Vector__XXX
 SG_ TEMPERATURE_13 : 40|8@1+ (0.5,-28) [-28|99.5] "C" Vector__XXX
 SG_ TEMPERATURE_14 : 48|8@1+ (0.5,-28) [-28|99.5] "C" Vector__XXX
 SG_ TEMPERATURE_15 : 56|8@1+ (0.5,-28) [-28|99.5] "C" Vector__XXX

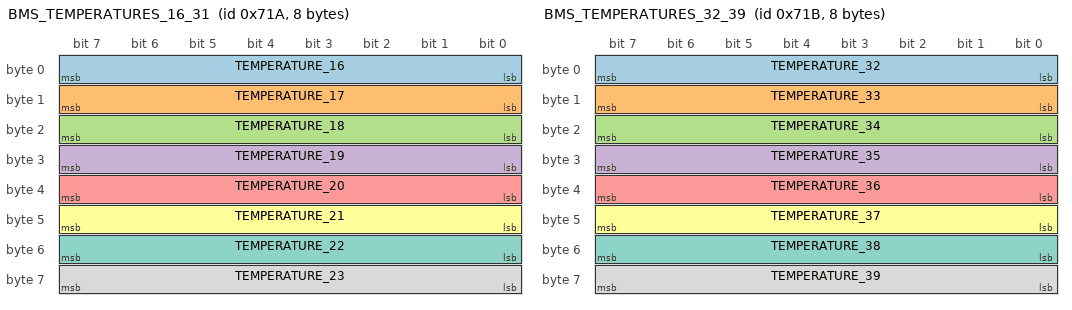
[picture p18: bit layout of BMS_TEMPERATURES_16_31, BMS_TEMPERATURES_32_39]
BO_ 1818 BMS_TEMPERATURES_16_31: 8 BMS
 SG_ TEMPERATURE_16 : 0|8@1+ (0.5,-28) [-28|99.5] "C" Vector__XXX
 SG_ TEMPERATURE_17 : 8|8@1+ (0.5,-28) [-28|99.5] "C" Vector__XXX
 SG_ TEMPERATURE_18 : 16|8@1+ (0.5,-28) [-28|99.5] "C" Vector__XXX
 SG_ TEMPERATURE_19 : 24|8@1+ (0.5,-28) [-28|99.5] "C" Vector__XXX
 SG_ TEMPERATURE_20 : 32|8@1+ (0.5,-28) [-28|99.5] "C" Vector__XXX
 SG_ TEMPERATURE_21 : 40|8@1+ (0.5,-28) [-28|99.5] "C" Vector__XXX
 SG_ TEMPERATURE_22 : 48|8@1+ (0.5,-28) [-28|99.5] "C" Vector__XXX
 SG_ TEMPERATURE_23 : 56|8@1+ (0.5,-28) [-28|99.5] "C" Vector__XXX

BO_ 1819 BMS_TEMPERATURES_32_39: 8 BMS
 SG_ TEMPERATURE_32 : 0|8@1+ (0.5,-28) [-28|99.5] "C" Vector__XXX
 SG_ TEMPERATURE_33 : 8|8@1+ (0.5,-28) [-28|99.5] "C" Vector__XXX
 SG_ TEMPERATURE_34 : 16|8@1+ (0.5,-28) [-28|99.5] "C" Vector__XXX
 SG_ TEMPERATURE_35 : 24|8@1+ (0.5,-28) [-28|99.5] "C" Vector__XXX
 SG_ TEMPERATURE_36 : 32|8@1+ (0.5,-28) [-28|99.5] "C" Vector__XXX
 SG_ TEMPERATURE_37 : 40|8@1+ (0.5,-28) [-28|99.5] "C" Vector__XXX
 SG_ TEMPERATURE_38 : 48|8@1+ (0.5,-28) [-28|99.5] "C" Vector__XXX
 SG_ TEMPERATURE_39 : 56|8@1+ (0.5,-28) [-28|99.5] "C" Vector__XXX

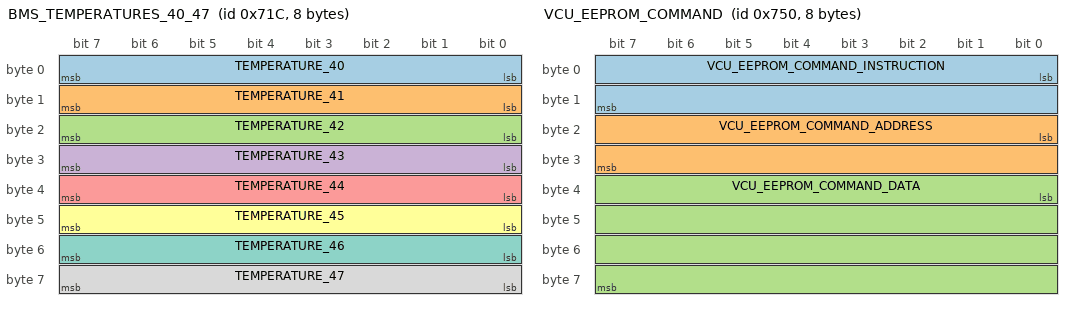
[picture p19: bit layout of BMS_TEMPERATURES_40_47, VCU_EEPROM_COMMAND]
BO_ 1820 BMS_TEMPERATURES_40_47: 8 BMS
 SG_ TEMPERATURE_40 : 0|8@1+ (0.5,-28) [-28|99.5] "C" Vector__XXX
 SG_ TEMPERATURE_41 : 8|8@1+ (0.5,-28) [-28|99.5] "C" Vector__XXX
 SG_ TEMPERATURE_42 : 16|8@1+ (0.5,-28) [-28|99.5] "C" Vector__XXX
 SG_ TEMPERATURE_43 : 24|8@1+ (0.5,-28) [-28|99.5] "C" Vector__XXX
 SG_ TEMPERATURE_44 : 32|8@1+ (0.5,-28) [-28|99.5] "C" Vector__XXX
 SG_ TEMPERATURE_45 : 40|8@1+ (0.5,-28) [-28|99.5] "C" Vector__XXX
 SG_ TEMPERATURE_46 : 48|8@1+ (0.5,-28) [-28|99.5] "C" Vector__XXX
 SG_ TEMPERATURE_47 : 56|8@1+ (0.5,-28) [-28|99.5] "C" Vector__XXX

BO_ 1821 BMS_TEMPERATURES_48_49: 8 BMS
 SG_ TEMPERATURE_48 : 0|8@1+ (0.5,-28) [-28|99.5] "C" Vector__XXX
 SG_ TEMPERATURE_49 : 8|8@1+ (0.5,-28) [-28|99.5] "C" Vector__XXX

BO_ 1872 VCU_EEPROM_COMMAND: 8 Vector__XXX
 SG_ VCU_EEPROM_COMMAND_INSTRUCTION : 0|16@1+ (1,0) [0|0] "" Vector__XXX
 SG_ VCU_EEPROM_COMMAND_ADDRESS : 16|16@1+ (1,0) [0|0] "" Vector__XXX
 SG_ VCU_EEPROM_COMMAND_DATA : 32|32@1+ (1,0) [0|0] "" Vector__XXX

BO_ 1873 VCU_EEPROM_RESPONSE: 8 Vector__XXX
 SG_ VCU_EEPROM_COMMAND_INSTRUCTION : 0|16@1+ (1,0) [0|0] "" Vector__XXX
 SG_ VCU_EEPROM_COMMAND_ADDRESS : 16|16@1+ (1,0) [0|0] "" Vector__XXX
 SG_ VCU_EEPROM_COMMAND_DATA : 32|32@1+ (1,0) [0|0] "" Vector__XXX

CM_ SG_ 1280 RL_TEMPERATURE_EXTERNAL "TODO(Barach): No documented scale factor";
CM_ SG_ 1280 RL_TEMPERATURE_SENSOR_MOTOR "TODO(Barach): No documented scale factor";

BA_DEF_  "BusType" STRING ;
BA_DEF_DEF_  "BusType" "CAN";
